AUTOSAR XML (schema 4-2-2)
package /AUTOSAR/Components
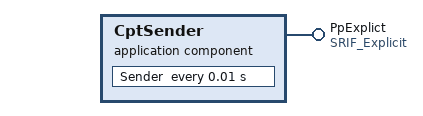
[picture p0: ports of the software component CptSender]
  application sw component type CptSender
    provide port PpExplict: provided-interface=SRIF_Explicit
    behavior IbSender
      timing event timingEvent_10: start-on-event=Sender, period=0.01
      runnable Sender: symbol=AppSenderRunnable
        data-send-points:
          access DataSendPointsPrimitive: accessed-variable=PpExplict.dataElementPrimitive
          access dataSendPointsArray: accessed-variable=PpExplict.dataElementArray
          access dataSendPointsStruct: accessed-variable=PpExplict.dataElementStruct
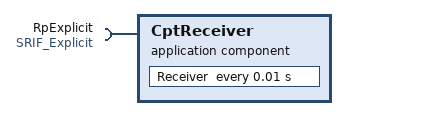
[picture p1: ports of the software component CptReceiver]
  application sw component type CptReceiver
    require port RpExplicit: required-interface=SRIF_Explicit
      required-com-specs:
        data-element=dataElementPrimitive, external-replacement=dataElementPrimitive, init-value=0
        data-element=dataElementStruct, init-value=fields=[0, 1, 2]
    behavior IbReceiver
      timing event timingEvent_10: start-on-event=Receiver, period=0.01
      runnable Receiver: symbol=AppReceiverRunnable
        data-receive-point-by-arguments:
          access DataReceiveByArgPrimitive: accessed-variable=RpExplicit.dataElementPrimitive
          access DataReceiveByArgArray: accessed-variable=RpExplicit.dataElementArray
          access DataReceiveByArgStruct: accessed-variable=RpExplicit.dataElementStruct
